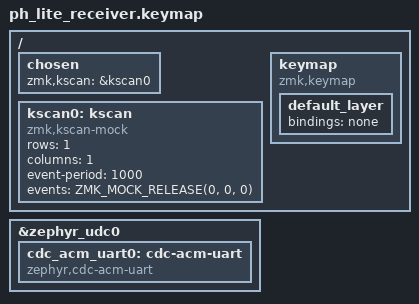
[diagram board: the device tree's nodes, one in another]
/* SPDX-License-Identifier: MIT */

#undef ZMK_BEHAVIORS_KEEP_ALL

#include <behaviors.dtsi>
#include <dt-bindings/zmk/kscan_mock.h>

/ {
    chosen {
        zmk,kscan = &kscan0;
    };

    kscan0: kscan {
        compatible = "zmk,kscan-mock";
        rows = <1>;
        columns = <1>;
        event-period = <1000>;
        events = <ZMK_MOCK_RELEASE(0, 0, 0)>;
    };

    keymap {
        compatible = "zmk,keymap";

        default_layer {
            bindings = <&none>;
        };
    };
};

&zephyr_udc0 {
    cdc_acm_uart0: cdc-acm-uart {
        compatible = "zephyr,cdc-acm-uart";
    };
};
